VERSION ""

NS_ :

BS_:

BU_: MASTER SENSOR GEO ANDROID MOTOR

BO_ 120 HEARTBEAT: 1 MASTER
 SG_ HEARTBEAT_cmd : 0|8@1+ (1,0) [0|0] "" SENSOR,MOTOR,ANDROID,GEO

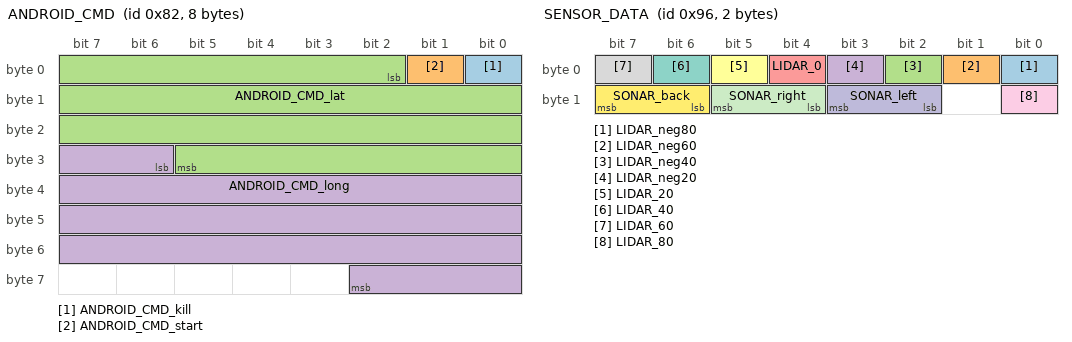
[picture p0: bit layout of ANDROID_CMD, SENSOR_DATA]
BO_ 130 ANDROID_CMD: 8 ANDROID
 SG_ ANDROID_CMD_kill : 0|1@1+ (1,0) [0|0] "" MASTER
 SG_ ANDROID_CMD_start : 1|1@1+ (1,0) [0|0] "" MASTER
 SG_ ANDROID_CMD_lat : 2|28@1+ (0.000001,-90.000000) [-90|90] "Degrees" MASTER
 SG_ ANDROID_CMD_long : 30|29@1+ (0.000001,-180.000000) [-180|180] "Degrees" MASTER

BO_ 140 CAR_CONTROL: 2 MASTER
 SG_ CAR_CONTROL_speed : 0|4@1+ (1,0) [0|0] "mph" MOTOR
 SG_ CAR_CONTROL_steer : 4|4@1+ (1,0) [0|0] "" MOTOR

BO_ 150 SENSOR_DATA: 2 SENSOR
 SG_ LIDAR_neg80 : 0|1@1+ (1,0) [0|1] "" MASTER,MOTOR,ANDROID
 SG_ LIDAR_neg60 : 1|1@1+ (1,0) [0|1] "" MASTER,MOTOR,ANDROID
 SG_ LIDAR_neg40 : 2|1@1+ (1,0) [0|1] "" MASTER,MOTOR,ANDROID
 SG_ LIDAR_neg20 : 3|1@1+ (1,0) [0|1] "" MASTER,MOTOR,ANDROID
 SG_ LIDAR_0 : 4|1@1+ (1,0) [0|1] "" MASTER,MOTOR,ANDROID
 SG_ LIDAR_20 : 5|1@1+ (1,0) [0|1] "" MASTER,MOTOR,ANDROID
 SG_ LIDAR_40 : 6|1@1+ (1,0) [0|1] "" MASTER,MOTOR,ANDROID
 SG_ LIDAR_60 : 7|1@1+ (1,0) [0|1] "" MASTER,MOTOR,ANDROID
 SG_ LIDAR_80 : 8|1@1+ (1,0) [0|1] "" MASTER,MOTOR,ANDROID
 SG_ SONAR_left : 10|2@1+ (1,0) [0|2] "" MASTER,MOTOR,ANDROID
 SG_ SONAR_right : 12|2@1+ (1,0) [0|2] "" MASTER,MOTOR,ANDROID
 SG_ SONAR_back : 14|2@1+ (1,0) [0|2] "" MASTER,MOTOR,ANDROID

BO_ 160 GPS_DATA: 8 GEO
 SG_ GPS_LATITUDE : 0|28@1+ (0.000001,-90.000000) [-90|90] "Degrees" MASTER,MOTOR,ANDROID
 SG_ GPS_LONGITUDE : 28|29@1+ (0.000001,-180.000000) [-180|180] "Degrees" MASTER,MOTOR,ANDROID

BO_ 170 COMPASS: 8 GEO
 SG_ CMP_HEADING : 0|32@1+ (1,0) [0|0] "Degrees" MASTER,MOTOR,ANDROID
 SG_ CMP_BEARING : 32|32@1+ (1,0) [0|0] "Degrees" MASTER,MOTOR,ANDROID

BO_ 180 MOTOR_DATA: 1 MOTOR
 SG_ CAR_SPEED : 0|5@1+ (1,0) [0|0] "mph" MASTER

CM_ BU_ MASTER "Master controller is heart of the system and will control other boards";
CM_ BU_ MOTOR "Motor will drive the wheels of car and display data on LCD";
CM_ BU_ SENSOR "Sensor will help in obstacle detection and avoidance";
CM_ BU_ GEO "Geo will help in navigation";
CM_ BU_ ANDROID "User sets destination and commands to start-stop the car";

BA_ "FieldType" SG_ 120 HEARTBEAT_cmd "HEARTBEAT_cmd";
BA_ "FieldType" SG_ 150 SONAR_left "SONAR_left";
BA_ "FieldType" SG_ 150 SONAR_right "SONAR_right";
BA_ "FieldType" SG_ 150 SONAR_back "SONAR_back";

VAL_ 120 HEARTBEAT_cmd 2 "HEARTBEAT_cmd_REBOOT" 1 "HEARTBEAT_cmd_SYNC" 0 "HEARTBEAT_cmd_NOOP" ;
VAL_ 150 SONAR_left 2 "SONAR_left_safe" 1 "SONAR_left_alert" 0 "SONAR_left_critical" ;
VAL_ 150 SONAR_right 2 "SONAR_right_safe" 1 "SONAR_right_alert" 0 "SONAR_right_critical" ;
VAL_ 150 SONAR_back 2 "SONAR_back_safe" 1 "SONAR_back_alert" 0 "SONAR_back_critical" ;
